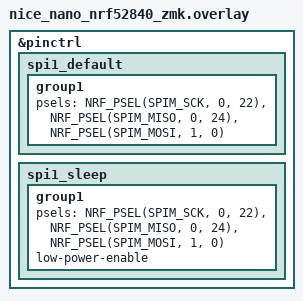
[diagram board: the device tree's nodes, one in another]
#include <dt-bindings/pinctrl/nrf-pinctrl.h>

// 将 SPI1 引脚重映射到 pro_micro 4/5/6
// BSP 默认占用 pro_micro 14/15/16，与键矩阵冲突，必须覆盖
&pinctrl {
    spi1_default: spi1_default {
        /delete-node/ group1;
        group1 {
            psels = <NRF_PSEL(SPIM_SCK,  0, 22)>,  // pro_micro 4 = P0.22
                    <NRF_PSEL(SPIM_MISO, 0, 24)>,  // pro_micro 5 = P0.24
                    <NRF_PSEL(SPIM_MOSI, 1,  0)>;  // pro_micro 6 = P1.00
        };
    };

    spi1_sleep: spi1_sleep {
        /delete-node/ group1;
        group1 {
            psels = <NRF_PSEL(SPIM_SCK,  0, 22)>,
                    <NRF_PSEL(SPIM_MISO, 0, 24)>,
                    <NRF_PSEL(SPIM_MOSI, 1,  0)>;
            low-power-enable;
        };
    };
};

